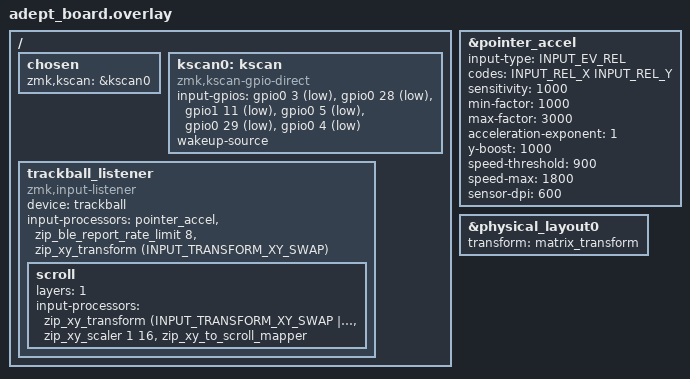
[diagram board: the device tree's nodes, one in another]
#include "adept.dtsi"
#include "pmw3610.dtsi"
#include "adept-layouts.dtsi"
#include <input/processors.dtsi>
#include <input/processors/report_rate_limit.dtsi>
#include <dt-bindings/zmk/input_transform.h>
#include <behaviors/input_gestures_accel.dtsi>

&pointer_accel { // this needs to be put BEFORE input-listener
    input-type = <INPUT_EV_REL>;
    codes = <INPUT_REL_X INPUT_REL_Y>;
    sensitivity = <1000>;
    min-factor = <1000>;
    max-factor = <3000>;
    acceleration-exponent = <1>;
    y-boost = <1000>;
    speed-threshold = <900>;
    speed-max = <1800>;
    sensor-dpi = <600>;
};

/* More about input processors: https://zmk.dev/docs/keymaps/input-processors#input-processors-overview */

&physical_layout0 {
    transform = <&matrix_transform>;
};

/ {
    chosen {
        zmk,kscan = &kscan0;
    };

    kscan0: kscan {
        compatible = "zmk,kscan-gpio-direct";
        input-gpios =
            <&gpio0  3 (GPIO_ACTIVE_LOW | GPIO_PULL_UP)>, // sw_1
            <&gpio0 28 (GPIO_ACTIVE_LOW | GPIO_PULL_UP)>, // sw_2
            <&gpio1 11 (GPIO_ACTIVE_LOW | GPIO_PULL_UP)>, // sw_6
            <&gpio0  5 (GPIO_ACTIVE_LOW | GPIO_PULL_UP)>, // sw_5
            <&gpio0 29 (GPIO_ACTIVE_LOW | GPIO_PULL_UP)>, // sw_3
            <&gpio0  4 (GPIO_ACTIVE_LOW | GPIO_PULL_UP)>; // sw_4
        wakeup-source;
    };

    trackball_listener { // listener for input device
        compatible = "zmk,input-listener";
        device = <&trackball>;
        input-processors =
            <&pointer_accel>,
            <&zip_ble_report_rate_limit 8>, // from badjeff's https://github.com/badjeff/zmk-input-processor-report-rate-limit/blob/main/dts/input/processors/report_rate_limit.dtsi
            <&zip_xy_transform (INPUT_TRANSFORM_XY_SWAP)>;

        scroll {
            layers = <1>; // scroll_layer
            input-processors =
            <&zip_xy_transform (INPUT_TRANSFORM_XY_SWAP | INPUT_TRANSFORM_Y_INVERT)>,
            <&zip_xy_scaler 1 16>,
            <&zip_xy_to_scroll_mapper>;
        };
    };
};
